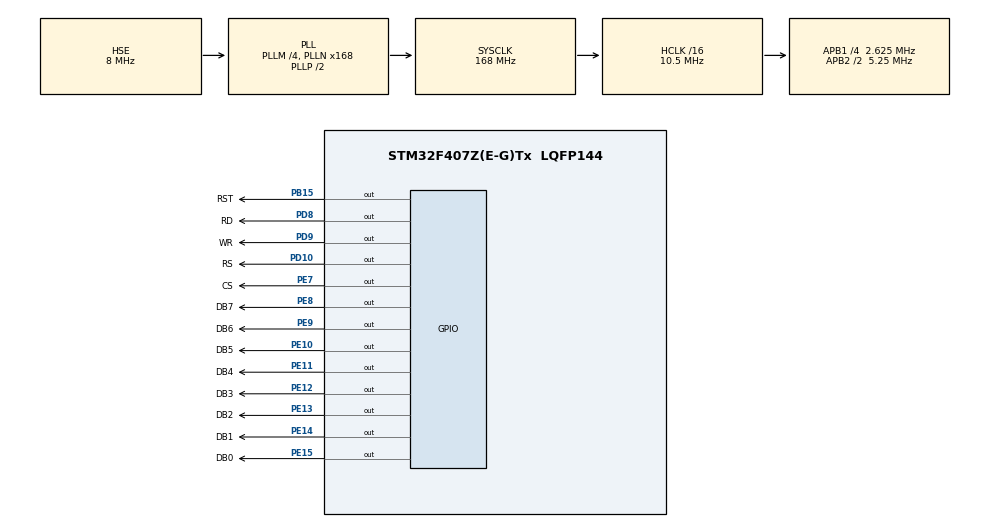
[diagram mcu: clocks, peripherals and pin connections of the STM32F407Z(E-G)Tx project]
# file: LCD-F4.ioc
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Mcu.Family=STM32F4
Mcu.Name=STM32F407Z(E-G)Tx
Mcu.Package=LQFP144
NVIC.PriorityGroup=NVIC_PRIORITYGROUP_4
PB15.GPIO_Label=RST
PB15.GPIO_ModeDefaultOutputPP=GPIO_MODE_OUTPUT_PP
PB15.GPIO_PuPd=GPIO_PULLUP
PB15.GPIO_Speed=GPIO_SPEED_FREQ_HIGH
PB15.PinState=GPIO_PIN_SET
PB15.Signal=GPIO_Output
PD10.GPIO_Label=RS
PD10.GPIO_ModeDefaultOutputPP=GPIO_MODE_OUTPUT_PP
PD10.GPIO_PuPd=GPIO_PULLUP
PD10.GPIO_Speed=GPIO_SPEED_FREQ_HIGH
PD10.PinState=GPIO_PIN_SET
PD10.Signal=GPIO_Output
PD8.GPIO_Label=RD
PD8.GPIO_ModeDefaultOutputPP=GPIO_MODE_OUTPUT_PP
PD8.GPIO_PuPd=GPIO_PULLUP
PD8.GPIO_Speed=GPIO_SPEED_FREQ_HIGH
PD8.PinState=GPIO_PIN_SET
PD8.Signal=GPIO_Output
PD9.GPIO_Label=WR
PD9.GPIO_ModeDefaultOutputPP=GPIO_MODE_OUTPUT_PP
PD9.GPIO_PuPd=GPIO_PULLUP
PD9.GPIO_Speed=GPIO_SPEED_FREQ_HIGH
PD9.PinState=GPIO_PIN_SET
PD9.Signal=GPIO_Output
PE10.GPIO_Label=DB5
PE10.GPIO_ModeDefaultOutputPP=GPIO_MODE_OUTPUT_PP
PE10.GPIO_PuPd=GPIO_PULLUP
PE10.GPIO_Speed=GPIO_SPEED_FREQ_HIGH
PE10.PinState=GPIO_PIN_SET
PE10.Signal=GPIO_Output
PE11.GPIO_Label=DB4
PE11.GPIO_ModeDefaultOutputPP=GPIO_MODE_OUTPUT_PP
PE11.GPIO_PuPd=GPIO_PULLUP
PE11.GPIO_Speed=GPIO_SPEED_FREQ_HIGH
PE11.PinState=GPIO_PIN_SET
PE11.Signal=GPIO_Output
PE12.GPIO_Label=DB3
PE12.GPIO_ModeDefaultOutputPP=GPIO_MODE_OUTPUT_PP
PE12.GPIO_PuPd=GPIO_PULLUP
PE12.GPIO_Speed=GPIO_SPEED_FREQ_HIGH
PE12.PinState=GPIO_PIN_SET
PE12.Signal=GPIO_Output
PE13.GPIO_Label=DB2
PE13.GPIO_ModeDefaultOutputPP=GPIO_MODE_OUTPUT_PP
PE13.GPIO_PuPd=GPIO_PULLUP
PE13.GPIO_Speed=GPIO_SPEED_FREQ_HIGH
PE13.PinState=GPIO_PIN_SET
PE13.Signal=GPIO_Output
PE14.GPIO_Label=DB1
PE14.GPIO_ModeDefaultOutputPP=GPIO_MODE_OUTPUT_PP
PE14.GPIO_PuPd=GPIO_PULLUP
PE14.GPIO_Speed=GPIO_SPEED_FREQ_HIGH
PE14.PinState=GPIO_PIN_SET
PE14.Signal=GPIO_Output
PE15.GPIO_Label=DB0
PE15.GPIO_ModeDefaultOutputPP=GPIO_MODE_OUTPUT_PP
PE15.GPIO_PuPd=GPIO_PULLUP
PE15.GPIO_Speed=GPIO_SPEED_FREQ_HIGH
PE15.PinState=GPIO_PIN_SET
PE15.Signal=GPIO_Output
PE7.GPIO_Label=CS
PE7.GPIO_ModeDefaultOutputPP=GPIO_MODE_OUTPUT_PP
PE7.GPIO_PuPd=GPIO_PULLUP
PE7.GPIO_Speed=GPIO_SPEED_FREQ_HIGH
PE7.PinState=GPIO_PIN_SET
PE7.Signal=GPIO_Output
PE8.GPIO_Label=DB7
PE8.GPIO_ModeDefaultOutputPP=GPIO_MODE_OUTPUT_PP
PE8.GPIO_PuPd=GPIO_PULLUP
PE8.GPIO_Speed=GPIO_SPEED_FREQ_HIGH
PE8.PinState=GPIO_PIN_SET
PE8.Signal=GPIO_Output
PE9.GPIO_Label=DB6
PE9.GPIO_ModeDefaultOutputPP=GPIO_MODE_OUTPUT_PP
PE9.GPIO_PuPd=GPIO_PULLUP
PE9.GPIO_Speed=GPIO_SPEED_FREQ_HIGH
PE9.PinState=GPIO_PIN_SET
PE9.Signal=GPIO_Output
PH0-OSC_IN.Mode=HSE-External-Oscillator
PH0-OSC_IN.Signal=RCC_OSC_IN
PH1-OSC_OUT.Mode=HSE-External-Oscillator
PH1-OSC_OUT.Signal=RCC_OSC_OUT
ProjectManager.HeapSize=0x200
ProjectManager.StackSize=0x400
ProjectManager.TargetToolchain=MDK-ARM V5
RCC.48MHZClocksFreq_Value=84000000
RCC.AHBCLKDivider=RCC_SYSCLK_DIV16
RCC.AHBFreq_Value=10500000
RCC.APB1CLKDivider=RCC_HCLK_DIV4
RCC.APB1Freq_Value=2625000
RCC.APB1TimFreq_Value=5250000
RCC.APB2CLKDivider=RCC_HCLK_DIV2
RCC.APB2Freq_Value=5250000
RCC.APB2TimFreq_Value=10500000
RCC.CortexFreq_Value=10500000
RCC.HCLKFreq_Value=10500000
RCC.HSE_VALUE=8000000
RCC.HSI_VALUE=16000000
RCC.LSE_VALUE=32768
RCC.PLLM=4
RCC.PLLN=168
RCC.PLLSourceVirtual=RCC_PLLSOURCE_HSE
RCC.SYSCLKFreq_VALUE=168000000
RCC.SYSCLKSource=RCC_SYSCLKSOURCE_PLLCLK
RCC.VCOOutputFreq_Value=336000000
board=LCD-F4

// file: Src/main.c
/**
  ******************************************************************************
  * File Name          : main.c
  * Description        : Main program body
  ******************************************************************************
  ** This notice applies to any and all portions of this file
  * that are not between comment pairs USER CODE BEGIN and
  * USER CODE END. Other portions of this file, whether
  * inserted by the user or by software development tools
  * are owned by their respective copyright owners.
  *
  * COPYRIGHT(c) 2018 STMicroelectronics
  *
  * Redistribution and use in source and binary forms, with or without modification,
  * are permitted provided that the following conditions are met:
  *   1. Redistributions of source code must retain the above copyright notice,
  *      this list of conditions and the following disclaimer.
  *   2. Redistributions in binary form must reproduce the above copyright notice,
  *      this list of conditions and the following disclaimer in the documentation
  *      and/or other materials provided with the distribution.
  *   3. Neither the name of STMicroelectronics nor the names of its contributors
  *      may be used to endorse or promote products derived from this software
  *      without specific prior written permission.
  *
  * THIS SOFTWARE IS PROVIDED BY THE COPYRIGHT HOLDERS AND CONTRIBUTORS "AS IS"
  * AND ANY EXPRESS OR IMPLIED WARRANTIES, INCLUDING, BUT NOT LIMITED TO, THE
  * IMPLIED WARRANTIES OF MERCHANTABILITY AND FITNESS FOR A PARTICULAR PURPOSE ARE
  * DISCLAIMED. IN NO EVENT SHALL THE COPYRIGHT HOLDER OR CONTRIBUTORS BE LIABLE
  * FOR ANY DIRECT, INDIRECT, INCIDENTAL, SPECIAL, EXEMPLARY, OR CONSEQUENTIAL
  * DAMAGES (INCLUDING, BUT NOT LIMITED TO, PROCUREMENT OF SUBSTITUTE GOODS OR
  * SERVICES; LOSS OF USE, DATA, OR PROFITS; OR BUSINESS INTERRUPTION) HOWEVER
  * CAUSED AND ON ANY THEORY OF LIABILITY, WHETHER IN CONTRACT, STRICT LIABILITY,
  * OR TORT (INCLUDING NEGLIGENCE OR OTHERWISE) ARISING IN ANY WAY OUT OF THE USE
  * OF THIS SOFTWARE, EVEN IF ADVISED OF THE POSSIBILITY OF SUCH DAMAGE.
  *
  ******************************************************************************
  */

#include "main.h"
#include "stm32f4xx_hal.h"
#include "led.h"
#include "delay.h"

//注意：改程序的系统时钟频率为10.5M

/* USER CODE BEGIN PV */
/* Private variables ---------------------------------------------------------*/

/* USER CODE END PV */

void SystemClock_Config(void);
static void MX_GPIO_Init(void);

/* USER CODE BEGIN PFP */
/* Private function prototypes -----------------------------------------------*/

/* USER CODE END PFP */

int main(void)
{

  /* MCU Configuration----------------------------------------------------------*/

  /* Reset of all peripherals, Initializes the Flash interface and the Systick. */
  HAL_Init();

  /* Configure the system clock */
  SystemClock_Config();

  /* Initialize all configured peripherals */
  MX_GPIO_Init();

  /* USER CODE BEGIN 2 */
    delay_init(10);
	LCD_Init(4551);
//	address(); //4551需要
	LCD_Clear(4551);
  /* USER CODE END 2 */

  /* Infinite loop */
  while (1)
  {

  }

}

/** System Clock Configuration
*/
void SystemClock_Config(void)
{

  RCC_OscInitTypeDef RCC_OscInitStruct;
  RCC_ClkInitTypeDef RCC_ClkInitStruct;

    /**Configure the main internal regulator output voltage
    */
  __HAL_RCC_PWR_CLK_ENABLE();

  __HAL_PWR_VOLTAGESCALING_CONFIG(PWR_REGULATOR_VOLTAGE_SCALE1);

    /**Initializes the CPU, AHB and APB busses clocks
    */
  RCC_OscInitStruct.OscillatorType = RCC_OSCILLATORTYPE_HSE;
  RCC_OscInitStruct.HSEState = RCC_HSE_ON;
  RCC_OscInitStruct.PLL.PLLState = RCC_PLL_ON;
  RCC_OscInitStruct.PLL.PLLSource = RCC_PLLSOURCE_HSE;
  RCC_OscInitStruct.PLL.PLLM = 4;
  RCC_OscInitStruct.PLL.PLLN = 168;
  RCC_OscInitStruct.PLL.PLLP = RCC_PLLP_DIV2;
  RCC_OscInitStruct.PLL.PLLQ = 4;
  if (HAL_RCC_OscConfig(&RCC_OscInitStruct) != HAL_OK)
  {
    _Error_Handler(__FILE__, __LINE__);
  }

    /**Initializes the CPU, AHB and APB busses clocks
    */
  RCC_ClkInitStruct.ClockType = RCC_CLOCKTYPE_HCLK|RCC_CLOCKTYPE_SYSCLK
                              |RCC_CLOCKTYPE_PCLK1|RCC_CLOCKTYPE_PCLK2;
  RCC_ClkInitStruct.SYSCLKSource = RCC_SYSCLKSOURCE_PLLCLK;
  RCC_ClkInitStruct.AHBCLKDivider = RCC_SYSCLK_DIV16;
  RCC_ClkInitStruct.APB1CLKDivider = RCC_HCLK_DIV4;
  RCC_ClkInitStruct.APB2CLKDivider = RCC_HCLK_DIV2;

  if (HAL_RCC_ClockConfig(&RCC_ClkInitStruct, FLASH_LATENCY_0) != HAL_OK)
  {
    _Error_Handler(__FILE__, __LINE__);
  }

    /**Configure the Systick interrupt time
    */
  HAL_SYSTICK_Config(HAL_RCC_GetHCLKFreq()/1000);

    /**Configure the Systick
    */
  HAL_SYSTICK_CLKSourceConfig(SYSTICK_CLKSOURCE_HCLK);

  /* SysTick_IRQn interrupt configuration */
  HAL_NVIC_SetPriority(SysTick_IRQn, 0, 0);
}

/** Configure pins as
        * Analog
        * Input
        * Output
        * EVENT_OUT
        * EXTI
*/
static void MX_GPIO_Init(void)
{

  GPIO_InitTypeDef GPIO_InitStruct;

  /* GPIO Ports Clock Enable */
  __HAL_RCC_GPIOH_CLK_ENABLE();
  __HAL_RCC_GPIOE_CLK_ENABLE();
  __HAL_RCC_GPIOB_CLK_ENABLE();
  __HAL_RCC_GPIOD_CLK_ENABLE();

  /*Configure GPIO pin Output Level */
  HAL_GPIO_WritePin(GPIOE, CS_Pin|DB7_Pin|DB6_Pin|DB5_Pin
                          |DB4_Pin|DB3_Pin|DB2_Pin|DB1_Pin
                          |DB0_Pin, GPIO_PIN_SET);

  /*Configure GPIO pin Output Level */
  HAL_GPIO_WritePin(RST_GPIO_Port, RST_Pin, GPIO_PIN_SET);

  /*Configure GPIO pin Output Level */
  HAL_GPIO_WritePin(GPIOD, RD_Pin|WR_Pin|RS_Pin, GPIO_PIN_SET);

  /*Configure GPIO pins : CS_Pin DB7_Pin DB6_Pin DB5_Pin
                           DB4_Pin DB3_Pin DB2_Pin DB1_Pin
                           DB0_Pin */
  GPIO_InitStruct.Pin = CS_Pin|DB7_Pin|DB6_Pin|DB5_Pin
                          |DB4_Pin|DB3_Pin|DB2_Pin|DB1_Pin
                          |DB0_Pin;
  GPIO_InitStruct.Mode = GPIO_MODE_OUTPUT_PP;
  GPIO_InitStruct.Pull = GPIO_PULLUP;
  GPIO_InitStruct.Speed = GPIO_SPEED_FREQ_VERY_HIGH;
  HAL_GPIO_Init(GPIOE, &GPIO_InitStruct);

  /*Configure GPIO pin : RST_Pin */
  GPIO_InitStruct.Pin = RST_Pin;
  GPIO_InitStruct.Mode = GPIO_MODE_OUTPUT_PP;
  GPIO_InitStruct.Pull = GPIO_PULLUP;
  GPIO_InitStruct.Speed = GPIO_SPEED_FREQ_VERY_HIGH;
  HAL_GPIO_Init(RST_GPIO_Port, &GPIO_InitStruct);

  /*Configure GPIO pins : RD_Pin WR_Pin RS_Pin */
  GPIO_InitStruct.Pin = RD_Pin|WR_Pin|RS_Pin;
  GPIO_InitStruct.Mode = GPIO_MODE_OUTPUT_PP;
  GPIO_InitStruct.Pull = GPIO_PULLUP;
  GPIO_InitStruct.Speed = GPIO_SPEED_FREQ_VERY_HIGH;
  HAL_GPIO_Init(GPIOD, &GPIO_InitStruct);

}

void _Error_Handler(char * file, int line)
{
  while(1)
  {
  }
}

/************************ (C) COPYRIGHT STMicroelectronics *****END OF FILE****/
